# CY8C5888AXI_LP096 register map
File version: 0.1
Registers are 8-bit, read-write, no defined reset value unless marked. A register's access mark holds for its fields unless they carry their own. Offsets are from the block's base; [hi:lo] are bit positions; 'fields as' and 'values as' point back to an identical list.

## EZI2C_Slave
Base 0x00000000
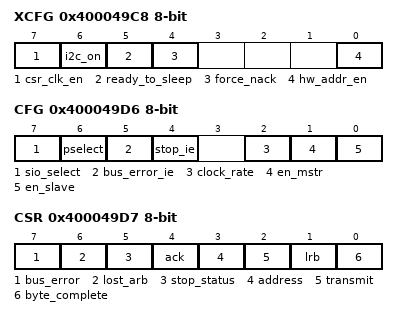
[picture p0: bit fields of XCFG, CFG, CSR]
0x400049C8 XCFG — I2C Extended Configuration Register
  [7] csr_clk_en — This bit is used for gating system clock for the blocks core logic that is not associated with AHB interface. Clock is made available to the core logic only when this bit is set to 1 and the input pin ext_clk_en is also active. If either of them is not active, the blocks core logic does not receive the system clock.
  [6] i2c_on — This bit should be set by the user during initial block configuration if the user wants to use the I2C block as wake-up source. Only when this bit set along with other bits mentioned in the sleep mode section, the I2C wakes up system from sleep on address match.
  [5] ready_to_sleep ro — Once the user sets the force_nack bit, the I2C block sets this bit if I2C is not busy or it waits for ongoing transaction to be completed and then sets this bit. As long as this bit is set, the I2C block is going to nack all the transactions.Clearing force_nack bit automatically clears this bit. HW clears this bit automatically on assertion of PD (Power Down)
  [4] force_nack — This bit must be set by the user before putting the device to sleep and wait for ready_to_sleep status bit to be set. This can be cleared by user by writing '0' and the HW clears it automatically on assertion of PD(Power Down)
  [0] hw_addr_en — When this bit is set to a '1', hardware address compare is enabled. On an address match, an interrupt is generated, CSR register bit 3 is set, and the clock is stalled until the CPU writes a 0 into the CSR register bit 3. The address is automatically ACKed on a match. On an address mismatch,no interrupt is generated, clock is not stalled, and bit 3 in the CSR register is set. The CPU must write a 0 into the CSR register bit 3 to clear it. The address is automatically NACKed on a mismatch. You must configure the compare address in the ADR register. When this bit is set to a '0', software address compare is enabled. An interrupt is generated, the clock is stalled, and CSR register bit 3 is set when the received address byte is available in the Data register; to enable the CPU to do a firmware address compare. The clock is stalled until the CPU writes a 0 into the CSR register bit 3. The functionality of this bit is independent of the data buffering mode.
0x400049CA ADDR — I2C Slave Adddress Register
  [6:0] slave_address — These seven bits hold the slave's own device address. These bits are held zero if I2C_CFG.en_mstr and I2C_CFG.en_slave are both zero.
0x400049D6 CFG — I2C Configuration Register
  [7] sio_select — I2C Pin Select for SCL/SDA lines from SIO1/SIO2, 0 = SCL and SDA lines get their inputs from SIO1 module.sclk_str1 and sda_ack1 are driven to SIO1 module and they get asserted once device wakes up from sleep. 1 = SCL and SDA lines get their inputs from SIO2 module. sclk_str2 and sda_ack2 are driven to SIO2 module and they get asserted once device wakes up from sleep. This bit is valid only when I2C.CFG[6] is asserted.
  [6] pselect — I2C Pin Select for SCL/SDA lines from GPIO/SIO, 0 = SCL and SDA lines get their inputs from GPIO module.sclk_str0 and sda_ack0 are driven to GPIO module and they get asserted once device wakes up from sleep. 1 = SCL and SDA lines get their inputs from one of the SIO Blocks that is chosen based on the configuration of bit I2C.CFG[7]
  [5] bus_error_ie — Bus Error Interrupt Enable 0 disabled 1 enabled. An interrupt is generated on the detection of a Bus error condition.
  [4] stop_ie — Stop Interrupt Enable 0 disabled 1 enabled. An interrupt is generated on the detection of a Stop condition.
  [2] clock_rate — 0 Samples/bit is 16, 1 Samples/bit is 32
  [1] en_mstr — Enables master mode for the device
  [0] en_slave — Enables Slave mode for the device
0x400049D7 CSR — I2C Control and Status Register
  [7] bus_error — It must be cleared by firmware by writing a '0' to the bit position. It is never cleared by the hardware. 1 a misplaced Start or Stop condition was detected. This bit is held zero if I2C_CFG.en_mstr and I2C_CFG.en_slave are both zero.
  [6] lost_arb — This bit is set immediately on lost arbitration; however, it does not cause an interrupt. This status may be checked after the following Byte Complete interrupt. Any Start detect or a write to the Start or Restart generate bits (MCSR register), when operating in Master mode, will also clear the bit. 1 lost Arbitration. This bit is held zero if I2C_CFG.en_mstr is zero.
  [5] stop_status — It must be cleared by firmware with write of '0' to the bit position. It is never cleared by the hardware. 1 a Stop condition was detected. This bit is held zero if I2C_CFG.en_mstr and I2C_CFG.en_slave are both zero.
  [4] ack — Acknowledge Out. Bit is automatically cleared by hardware on a Byte Complete event. 0 nack the last received byte. 1 ack the last received byte
  [3] address — It must be cleared by firmware with write of '0' to the bit position. 1 the received byte is a slave address. This bit is held zero if I2C_CFG.en_mstr and I2C_CFG.en_slave are both zero
  [2] transmit — Bit is set by firmware to define the direction of the byte transfer. Any Start detect will clear the bit. 0 receive mode 1 transmit mode. This bit is held zero if I2C_CFG.en_mstr and I2C_CFG.en_slave are both zero.
  [1] lrb — Last Received Bit. The value of the 9th bit in a Transmit sequence, which is the acknowledge bit from the receiver. Any Start detect or a write to the Start or Restart generate bits, when operating in Master mode, will also clear the bit. 0 last transmitted byte was ACK'ed by the receiver. 1 last transmitted byte was NACK'ed by the receiver. This bit is held zero if I2C_CFG.en_mstr and I2C_CFG.en_slave are both zero.
  [0] byte_complete — Transmit/Receive Mode: 0 no completed transmit/receive since last cleared by firmware. Any Start detect or a write to the start or Restart generate bits, when operating in Master mode, will also clear the bit. Transmit mode: 1 eight bits of data have been transmitted and an ACK or NACK has been received. Receive mode: 1 eight bits of data have been received. This bit is held zero if I2C_CFG.en_mstr and I2C_CFG.en_slave are both zero.
0x400049D8 DATA — I2C Data Register
  [7:0] data — Read received data or write data to transmit. These bits are held zero if I2C_CFG.en_mstr and I2C_CFG.en_slave are both zero.
0x400049DB CLK_DIV1 — I2C Clock Divide Factor Register-1
  [7:0] Div — The configuration of this register along with that in register CLK_DIV2 defines the factor by which the SYSCLK will be divided in the I2C block. These bits are held zero if I2C_CFG.en_mstr and I2C_CFG.en_slave are both zero.
0x400049DC CLK_DIV2 — I2C Clock Divide Factor Register-2
  [1:0] Div — The configuration of this register along with that in register CLK_DIV1 defines the factor by whichthe SYSCLK will be divided in the I2C block. These bits are held zero if I2C_CFG.en_mstr and I2C_CFG.en_slave are both zero.

## Right_QuadDec
Base 0x00000000
0x40006406 Right_QuadDec_Cnt16_COUNTER 16-bit — Counter value
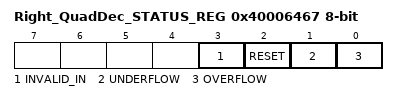
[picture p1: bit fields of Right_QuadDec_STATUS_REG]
0x40006467 Right_QuadDec_STATUS_REG — Quadrature Decoder Status Register
  [3] INVALID_IN ro — Invalid state transition on the A and B inputs
  [2] RESET ro — Counter Reset due index
  [1] UNDERFLOW ro — Counter underflow
  [0] OVERFLOW ro — Counter overflow

## Right_QuadDec_Cnt16
Base 0x00000000
0x40006406 Right_QuadDec_Cnt16_COUNTER 16-bit — UDB.A0 - Current Counter Value
0x40006426 Right_QuadDec_Cnt16_PERIOD 16-bit — UDB.D0 - Assigned Period
0x40006436 Right_QuadDec_Cnt16_COMPARE 16-bit — UDB.D1 - Assigned Compare Value
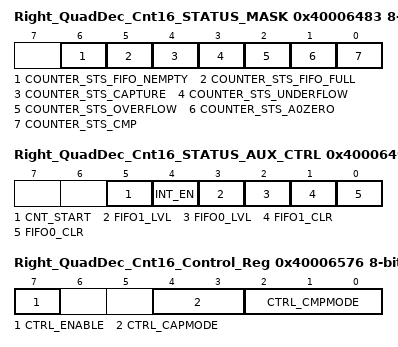
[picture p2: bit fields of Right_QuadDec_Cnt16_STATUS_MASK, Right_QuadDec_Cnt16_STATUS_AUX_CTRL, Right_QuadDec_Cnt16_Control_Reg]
0x40006483 Right_QuadDec_Cnt16_STATUS_MASK — UDB Status bits Interrupt Mask Enable Register
  [6] COUNTER_STS_FIFO_NEMPTY — FIFO Not Empty Status
  [5] COUNTER_STS_FIFO_FULL — FIFO Full Status
  [4] COUNTER_STS_CAPTURE — Capture Status
  [3] COUNTER_STS_UNDERFLOW — Underflow status
  [2] COUNTER_STS_OVERFLOW — Overflow status
  [1] COUNTER_STS_A0ZERO — A0 Zero ouput status
  [0] COUNTER_STS_CMP — Compare output status
0x40006493 Right_QuadDec_Cnt16_STATUS_AUX_CTRL — UDB Auxilliary Control Register
  [5] CNT_START — FIFO0 clear
    0=E_CNT_START0 (Disable counter); 1=E_CNT_START1 (Enable counter)
  [4] INT_EN
    0=E_INT_EN0 (Interrupt disabled); 1=E_INT_EN1 (Interrupt enabled)
  [3] FIFO1_LVL — FIFO level
    0=E_FIFO_LVL_0 (FIFO LVL: input mode: FIFO not full; output mode: FIFO not empty); 1=E_FIFO_LVL_1 (FIFO LVL: input mode: FIFO at least 1/2 empty; output mode: FIFO at least 1/2 full)
  [2] FIFO0_LVL — FIFO level
    values as FIFO1_LVL
  [1] FIFO1_CLR — FIFO1 clear
    0=E_FIFO_CLR_0 (Normal FIFO operation); 1=E_FIFO_CLR_1 (Clear FIFO state)
  [0] FIFO0_CLR — FIFO0 clear
    values as FIFO1_CLR
0x40006576 Right_QuadDec_Cnt16_Control_Reg — UDB Control Register - Assigned Control Register Value
  [7] CTRL_ENABLE — Enable Counter
  [4:3] CTRL_CAPMODE — Capture mode
  [2:0] CTRL_CMPMODE — Compare mode

## Right_HB25_PWM
Base 0x00000000
0x40006420 Right_HB25_PWM_COMPARE_Reg 16-bit — UDB.D0 - Assigned Compare Value
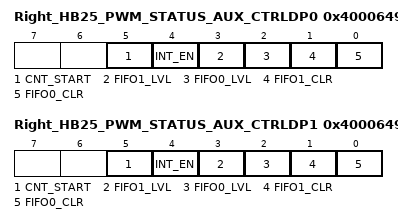
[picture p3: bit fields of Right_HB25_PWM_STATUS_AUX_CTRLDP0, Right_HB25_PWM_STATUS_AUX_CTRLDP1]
0x40006490 Right_HB25_PWM_STATUS_AUX_CTRLDP0 — UDB Auxilliary Control Register
  [5] CNT_START — FIFO0 clear
    0=E_CNT_START0 (Disable counter); 1=E_CNT_START1 (Enable counter)
  [4] INT_EN
    0=E_INT_EN0 (Interrupt disabled); 1=E_INT_EN1 (Interrupt enabled)
  [3] FIFO1_LVL — FIFO level
    0=E_FIFO_LVL_0 (FIFO LVL: input mode: FIFO not full; output mode: FIFO not empty); 1=E_FIFO_LVL_1 (FIFO LVL: input mode: FIFO at least 1/2 empty; output mode: FIFO at least 1/2 full)
  [2] FIFO0_LVL — FIFO level
    values as FIFO1_LVL
  [1] FIFO1_CLR — FIFO1 clear
    0=E_FIFO_CLR_0 (Normal FIFO operation); 1=E_FIFO_CLR_1 (Clear FIFO state)
  [0] FIFO0_CLR — FIFO0 clear
    values as FIFO1_CLR
0x40006491 Right_HB25_PWM_STATUS_AUX_CTRLDP1 — UDB Auxilliary Control Register
  fields as Right_HB25_PWM_STATUS_AUX_CTRLDP0
